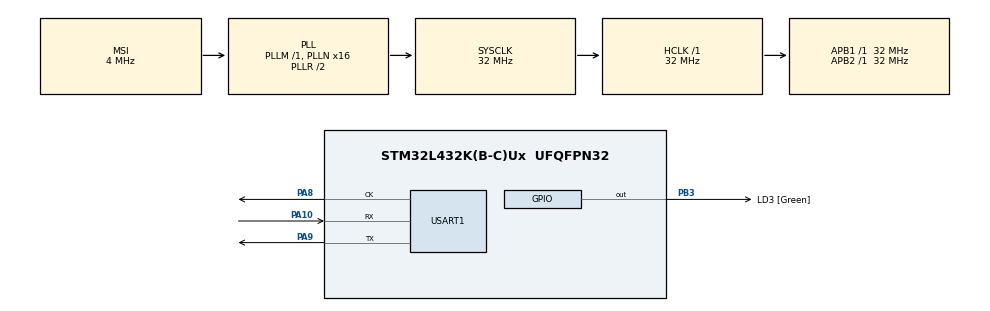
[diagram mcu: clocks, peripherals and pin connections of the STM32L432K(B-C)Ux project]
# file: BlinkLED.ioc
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Mcu.Family=STM32L4
Mcu.Name=STM32L432K(B-C)Ux
Mcu.Package=UFQFPN32
NVIC.PriorityGroup=NVIC_PRIORITYGROUP_4
PA0.GPIO_Label=MCO [High speed clock in]
PA0.Signal=RCC_CK_IN
PA10.Mode=Synchronous
PA10.Signal=USART1_RX
PA13\ (JTMS-SWDIO).GPIO_Label=SWDIO
PA13\ (JTMS-SWDIO).Signal=SYS_JTMS-SWDIO
PA14\ (JTCK-SWCLK).GPIO_Label=SWCLK
PA14\ (JTCK-SWCLK).Signal=SYS_JTCK-SWCLK
PA15\ (JTDI).GPIO_Label=VCP_RX
PA15\ (JTDI).Signal=USART2_RX
PA2.GPIO_Label=VCP_TX
PA2.Signal=USART2_TX
PA8.Mode=Synchronous
PA8.Signal=USART1_CK
PA9.Mode=Synchronous
PA9.Signal=USART1_TX
PB3\ (JTDO-TRACESWO).GPIO_Label=LD3 [Green]
PB3\ (JTDO-TRACESWO).Signal=GPIO_Output
PC14-OSC32_IN\ (PC14).Signal=RCC_OSC32_IN
PC15-OSC32_OUT\ (PC15).Signal=RCC_OSC32_OUT
ProjectManager.HeapSize=0x200
ProjectManager.StackSize=0x400
ProjectManager.TargetToolchain=SW4STM32
RCC.AHBFreq_Value=32000000
RCC.APB1Freq_Value=32000000
RCC.APB1TimFreq_Value=32000000
RCC.APB2Freq_Value=32000000
RCC.APB2TimFreq_Value=32000000
RCC.CortexFreq_Value=32000000
RCC.HCLKFreq_Value=32000000
RCC.HSE_VALUE=8000000
RCC.HSI16_VALUE=16000000
RCC.HSI48_VALUE=48000000
RCC.HSI_VALUE=16000000
RCC.LSE_VALUE=32768
RCC.MSI_VALUE=4000000
RCC.PLLMUL=RCC_PLLMUL_4
RCC.PLLN=16
RCC.SYSCLKFreq_VALUE=32000000
RCC.SYSCLKSource=RCC_SYSCLKSOURCE_PLLCLK
RCC.VCOOutputFreq_Value=64000000
USART1.VirtualMode-Synchronous=VM_SYNC
board=NUCLEO-L432KC

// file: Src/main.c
/**
  ******************************************************************************
  * File Name          : main.c
  * Description        : Main program body
  ******************************************************************************
  ** This notice applies to any and all portions of this file
  * that are not between comment pairs USER CODE BEGIN and
  * USER CODE END. Other portions of this file, whether
  * inserted by the user or by software development tools
  * are owned by their respective copyright owners.
  *
  * COPYRIGHT(c) 2017 STMicroelectronics
  *
  * Redistribution and use in source and binary forms, with or without modification,
  * are permitted provided that the following conditions are met:
  *   1. Redistributions of source code must retain the above copyright notice,
  *      this list of conditions and the following disclaimer.
  *   2. Redistributions in binary form must reproduce the above copyright notice,
  *      this list of conditions and the following disclaimer in the documentation
  *      and/or other materials provided with the distribution.
  *   3. Neither the name of STMicroelectronics nor the names of its contributors
  *      may be used to endorse or promote products derived from this software
  *      without specific prior written permission.
  *
  * THIS SOFTWARE IS PROVIDED BY THE COPYRIGHT HOLDERS AND CONTRIBUTORS "AS IS"
  * AND ANY EXPRESS OR IMPLIED WARRANTIES, INCLUDING, BUT NOT LIMITED TO, THE
  * IMPLIED WARRANTIES OF MERCHANTABILITY AND FITNESS FOR A PARTICULAR PURPOSE ARE
  * DISCLAIMED. IN NO EVENT SHALL THE COPYRIGHT HOLDER OR CONTRIBUTORS BE LIABLE
  * FOR ANY DIRECT, INDIRECT, INCIDENTAL, SPECIAL, EXEMPLARY, OR CONSEQUENTIAL
  * DAMAGES (INCLUDING, BUT NOT LIMITED TO, PROCUREMENT OF SUBSTITUTE GOODS OR
  * SERVICES; LOSS OF USE, DATA, OR PROFITS; OR BUSINESS INTERRUPTION) HOWEVER
  * CAUSED AND ON ANY THEORY OF LIABILITY, WHETHER IN CONTRACT, STRICT LIABILITY,
  * OR TORT (INCLUDING NEGLIGENCE OR OTHERWISE) ARISING IN ANY WAY OUT OF THE USE
  * OF THIS SOFTWARE, EVEN IF ADVISED OF THE POSSIBILITY OF SUCH DAMAGE.
  *
  ******************************************************************************
  */
#include "main.h"
#include "stm32l4xx_hal.h"

USART_HandleTypeDef husart1;

/* USER CODE BEGIN PV */
/* Private variables ---------------------------------------------------------*/

/* USER CODE END PV */

void SystemClock_Config(void);
static void MX_GPIO_Init(void);
static void MX_USART1_Init(void);

/* USER CODE BEGIN PFP */
/* Private function prototypes -----------------------------------------------*/

/* USER CODE END PFP */

int main(void)
{

  /* MCU Configuration----------------------------------------------------------*/

  /* Reset of all peripherals, Initializes the Flash interface and the Systick. */
  HAL_Init();

  /* Configure the system clock */
  SystemClock_Config();

  /* Initialize all configured peripherals */
  MX_GPIO_Init();
  MX_USART1_Init();

  /* Infinite loop */
  while (1)
  {

  /* USER CODE BEGIN 3 */
	  HAL_GPIO_WritePin(LD3_GPIO_Port, LD3_Pin, 0);
	  HAL_Delay(1000);
	  HAL_GPIO_WritePin(LD3_GPIO_Port, LD3_Pin, 1);
	  HAL_Delay(1000);
  }
  /* USER CODE END 3 */

}

/** System Clock Configuration
*/
void SystemClock_Config(void)
{

  RCC_OscInitTypeDef RCC_OscInitStruct;
  RCC_ClkInitTypeDef RCC_ClkInitStruct;
  RCC_PeriphCLKInitTypeDef PeriphClkInit;

    /**Initializes the CPU, AHB and APB busses clocks
    */
  RCC_OscInitStruct.OscillatorType = RCC_OSCILLATORTYPE_MSI;
  RCC_OscInitStruct.MSIState = RCC_MSI_ON;
  RCC_OscInitStruct.MSICalibrationValue = 0;
  RCC_OscInitStruct.MSIClockRange = RCC_MSIRANGE_6;
  RCC_OscInitStruct.PLL.PLLState = RCC_PLL_ON;
  RCC_OscInitStruct.PLL.PLLSource = RCC_PLLSOURCE_MSI;
  RCC_OscInitStruct.PLL.PLLM = 1;
  RCC_OscInitStruct.PLL.PLLN = 16;
  RCC_OscInitStruct.PLL.PLLP = RCC_PLLP_DIV7;
  RCC_OscInitStruct.PLL.PLLQ = RCC_PLLQ_DIV2;
  RCC_OscInitStruct.PLL.PLLR = RCC_PLLR_DIV2;
  if (HAL_RCC_OscConfig(&RCC_OscInitStruct) != HAL_OK)
  {
    _Error_Handler(__FILE__, __LINE__);
  }

    /**Initializes the CPU, AHB and APB busses clocks
    */
  RCC_ClkInitStruct.ClockType = RCC_CLOCKTYPE_HCLK|RCC_CLOCKTYPE_SYSCLK
                              |RCC_CLOCKTYPE_PCLK1|RCC_CLOCKTYPE_PCLK2;
  RCC_ClkInitStruct.SYSCLKSource = RCC_SYSCLKSOURCE_PLLCLK;
  RCC_ClkInitStruct.AHBCLKDivider = RCC_SYSCLK_DIV1;
  RCC_ClkInitStruct.APB1CLKDivider = RCC_HCLK_DIV1;
  RCC_ClkInitStruct.APB2CLKDivider = RCC_HCLK_DIV1;

  if (HAL_RCC_ClockConfig(&RCC_ClkInitStruct, FLASH_LATENCY_1) != HAL_OK)
  {
    _Error_Handler(__FILE__, __LINE__);
  }

  PeriphClkInit.PeriphClockSelection = RCC_PERIPHCLK_USART1;
  PeriphClkInit.Usart1ClockSelection = RCC_USART1CLKSOURCE_PCLK2;
  if (HAL_RCCEx_PeriphCLKConfig(&PeriphClkInit) != HAL_OK)
  {
    _Error_Handler(__FILE__, __LINE__);
  }

    /**Configure the main internal regulator output voltage
    */
  if (HAL_PWREx_ControlVoltageScaling(PWR_REGULATOR_VOLTAGE_SCALE1) != HAL_OK)
  {
    _Error_Handler(__FILE__, __LINE__);
  }

    /**Configure the Systick interrupt time
    */
  HAL_SYSTICK_Config(HAL_RCC_GetHCLKFreq()/1000);

    /**Configure the Systick
    */
  HAL_SYSTICK_CLKSourceConfig(SYSTICK_CLKSOURCE_HCLK);

  /* SysTick_IRQn interrupt configuration */
  HAL_NVIC_SetPriority(SysTick_IRQn, 0, 0);
}

/* USART1 init function */
static void MX_USART1_Init(void)
{

  husart1.Instance = USART1;
  husart1.Init.BaudRate = 115200;
  husart1.Init.WordLength = USART_WORDLENGTH_7B;
  husart1.Init.StopBits = USART_STOPBITS_1;
  husart1.Init.Parity = USART_PARITY_NONE;
  husart1.Init.Mode = USART_MODE_TX_RX;
  husart1.Init.CLKPolarity = USART_POLARITY_LOW;
  husart1.Init.CLKPhase = USART_PHASE_1EDGE;
  husart1.Init.CLKLastBit = USART_LASTBIT_DISABLE;
  if (HAL_USART_Init(&husart1) != HAL_OK)
  {
    _Error_Handler(__FILE__, __LINE__);
  }

}

/** Configure pins as
        * Analog
        * Input
        * Output
        * EVENT_OUT
        * EXTI
     PA2   ------> USART2_TX
     PA15 (JTDI)   ------> USART2_RX
*/
static void MX_GPIO_Init(void)
{

  GPIO_InitTypeDef GPIO_InitStruct;

  /* GPIO Ports Clock Enable */
  __HAL_RCC_GPIOC_CLK_ENABLE();
  __HAL_RCC_GPIOA_CLK_ENABLE();
  __HAL_RCC_GPIOB_CLK_ENABLE();

  /*Configure GPIO pin Output Level */
  HAL_GPIO_WritePin(LD3_GPIO_Port, LD3_Pin, GPIO_PIN_RESET);

  /*Configure GPIO pin : VCP_TX_Pin */
  GPIO_InitStruct.Pin = VCP_TX_Pin;
  GPIO_InitStruct.Mode = GPIO_MODE_AF_PP;
  GPIO_InitStruct.Pull = GPIO_NOPULL;
  GPIO_InitStruct.Speed = GPIO_SPEED_FREQ_VERY_HIGH;
  GPIO_InitStruct.Alternate = GPIO_AF7_USART2;
  HAL_GPIO_Init(VCP_TX_GPIO_Port, &GPIO_InitStruct);

  /*Configure GPIO pin : VCP_RX_Pin */
  GPIO_InitStruct.Pin = VCP_RX_Pin;
  GPIO_InitStruct.Mode = GPIO_MODE_AF_PP;
  GPIO_InitStruct.Pull = GPIO_NOPULL;
  GPIO_InitStruct.Speed = GPIO_SPEED_FREQ_VERY_HIGH;
  GPIO_InitStruct.Alternate = GPIO_AF3_USART2;
  HAL_GPIO_Init(VCP_RX_GPIO_Port, &GPIO_InitStruct);

  /*Configure GPIO pin : LD3_Pin */
  GPIO_InitStruct.Pin = LD3_Pin;
  GPIO_InitStruct.Mode = GPIO_MODE_OUTPUT_PP;
  GPIO_InitStruct.Pull = GPIO_NOPULL;
  GPIO_InitStruct.Speed = GPIO_SPEED_FREQ_LOW;
  HAL_GPIO_Init(LD3_GPIO_Port, &GPIO_InitStruct);

}

void _Error_Handler(char * file, int line)
{
  while(1)
  {
  }
}

/************************ (C) COPYRIGHT STMicroelectronics *****END OF FILE****/
